# nrf5340_network register map
Vendor: Nordic Semiconductor; Series: nrf53; File version: 1
CPU: CM33 r0p4, little endian, MPU, no FPU, 3 interrupt priority bits, 30 interrupts
Registers are 32-bit, read-write, reset 0x0 unless marked. A register's access mark holds for its fields unless they carry their own. Offsets are from the block's base; [hi:lo] are bit positions; lines under a group give offsets from that group; {n}, {i} and the like mark numbered series; 'fields as' and 'values as' point back to an identical list.

## AAR_NS — Accelerated Address Resolver
Base 0x4100E000
0x00 TASKS_START wo — Start resolving addresses based on IRKs specified in the IRK data structure
  [0] TASKS_START
    1=Trigger task
0x08 TASKS_STOP wo — Stop resolving addresses
  [0] TASKS_STOP
    1=Trigger task
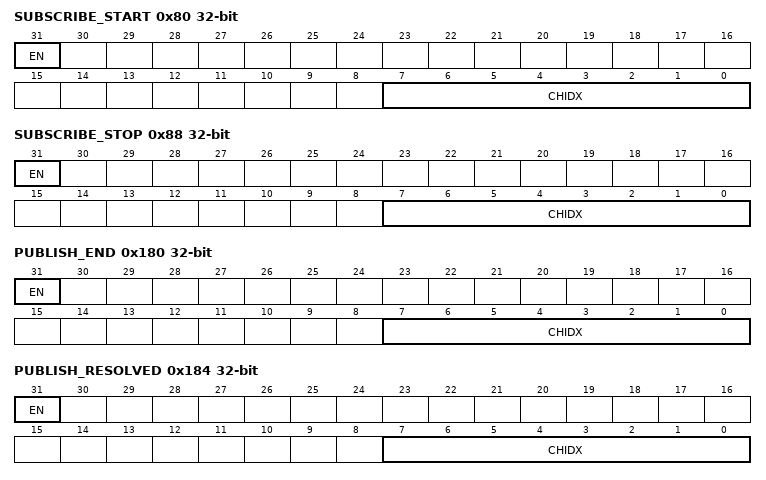
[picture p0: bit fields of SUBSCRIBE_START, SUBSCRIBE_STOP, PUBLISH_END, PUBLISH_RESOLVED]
0x80 SUBSCRIBE_START — Subscribe configuration for task START
  [31] EN
    0=Disabled (Disable subscription); 1=Enabled (Enable subscription)
  [7:0] CHIDX — DPPI channel that task START will subscribe to
0x88 SUBSCRIBE_STOP — Subscribe configuration for task STOP
  [31] EN
    values as SUBSCRIBE_START.EN
  [7:0] CHIDX — DPPI channel that task STOP will subscribe to
0x100 EVENTS_END — Address resolution procedure complete
  [0] EVENTS_END
    0=NotGenerated (Event not generated); 1=Generated (Event generated)
0x104 EVENTS_RESOLVED — Address resolved
  [0] EVENTS_RESOLVED
    values as EVENTS_END.EVENTS_END
0x108 EVENTS_NOTRESOLVED — Address not resolved
  [0] EVENTS_NOTRESOLVED
    values as EVENTS_END.EVENTS_END
0x180 PUBLISH_END — Publish configuration for event END
  [31] EN
    0=Disabled (Disable publishing); 1=Enabled (Enable publishing)
  [7:0] CHIDX — DPPI channel that event END will publish to.
0x184 PUBLISH_RESOLVED — Publish configuration for event RESOLVED
  [31] EN
    values as PUBLISH_END.EN
  [7:0] CHIDX — DPPI channel that event RESOLVED will publish to.
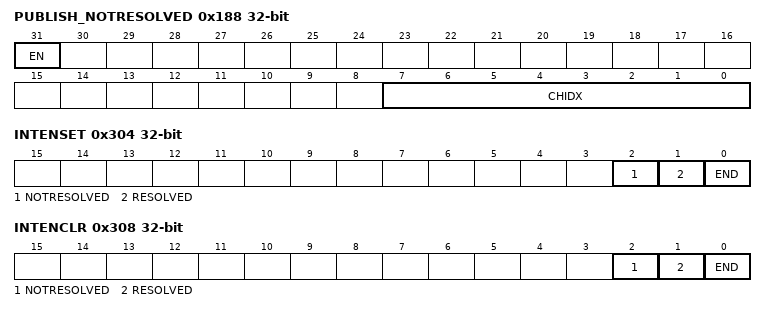
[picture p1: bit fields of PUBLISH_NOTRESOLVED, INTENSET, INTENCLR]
0x188 PUBLISH_NOTRESOLVED — Publish configuration for event NOTRESOLVED
  [31] EN
    values as PUBLISH_END.EN
  [7:0] CHIDX — DPPI channel that event NOTRESOLVED will publish to.
0x304 INTENSET — Enable interrupt
  [all] fields
    on read: 0=Disabled (Read: Disabled); 1=Enabled (Read: Enabled) | on write: 1=Set (Enable)
  [2] NOTRESOLVED — Write '1' to enable interrupt for event NOTRESOLVED
  [1] RESOLVED — Write '1' to enable interrupt for event RESOLVED
  [0] END — Write '1' to enable interrupt for event END
0x308 INTENCLR — Disable interrupt
  [all] fields
    on read: 0=Disabled (Read: Disabled); 1=Enabled (Read: Enabled) | on write: 1=Clear (Disable)
  [2] NOTRESOLVED — Write '1' to disable interrupt for event NOTRESOLVED
  [1] RESOLVED — Write '1' to disable interrupt for event RESOLVED
  [0] END — Write '1' to disable interrupt for event END
0x400 STATUS ro — Resolution status
  [3:0] STATUS — The IRK that was used last time an address was resolved
0x500 ENABLE — Enable AAR
  [1:0] ENABLE — Enable or disable AAR
    0=Disabled; 3=Enabled
0x504 NIRK reset 0x1 — Number of IRKs
  [4:0] NIRK — Number of Identity Root Keys available in the IRK data structure
0x508 IRKPTR — Pointer to IRK data structure
  [31:0] IRKPTR — Pointer to the IRK data structure
0x510 ADDRPTR — Pointer to the resolvable address
  [31:0] ADDRPTR — Pointer to the resolvable address (6-bytes)
0x514 SCRATCHPTR — Pointer to data area used for temporary storage
  [31:0] SCRATCHPTR — Pointer to a scratch data area used for temporary storage during resolution. A space of minimum 3 bytes must be reserved.

## DPPIC_NS — Distributed programmable peripheral interconnect controller
Base 0x4100F000
{0x0+8i} TASKS_CHG[{i}] (i=0..5) group — Channel group tasks
  0x00 EN wo — Description cluster: Enable channel group n
    [0] EN — Enable channel group n
      1=Trigger task
  0x04 DIS wo — Description cluster: Disable channel group n
    [0] DIS — Disable channel group n
      1=Trigger task
{0x80+8i} SUBSCRIBE_CHG[{i}] (i=0..5) group — Subscribe configuration for tasks
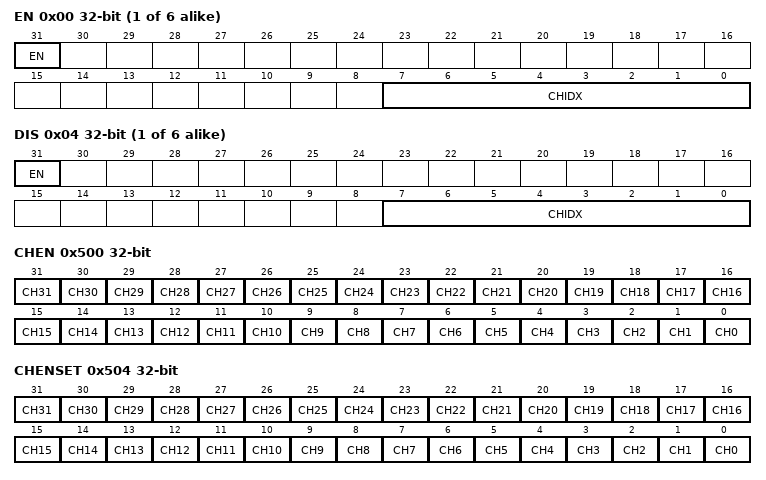
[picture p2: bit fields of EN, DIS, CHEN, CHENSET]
  0x00 EN — Description cluster: Subscribe configuration for task CHG[n].EN
    [31] EN
      0=Disabled (Disable subscription); 1=Enabled (Enable subscription)
    [7:0] CHIDX — DPPI channel that task CHG[n].EN will subscribe to
  0x04 DIS — Description cluster: Subscribe configuration for task CHG[n].DIS
    [31] EN
      values as SUBSCRIBE_CHG[0].EN.EN
    [7:0] CHIDX — DPPI channel that task CHG[n].DIS will subscribe to
0x500 CHEN — Channel enable register
  [all] fields
    0=Disabled (Disable channel); 1=Enabled (Enable channel)
  [n] CH{n} (n=0..31) — Enable or disable channel {n}
0x504 CHENSET write-1-sets — Channel enable set register
  [all] fields
    on read: 0=Disabled (Read: Channel disabled); 1=Enabled (Read: Channel enabled) | on write: 1=Set (Write: Enable channel)
  [n] CH{n} (n=0..31) — Channel {n} enable set register. Writing 0 has no effect.
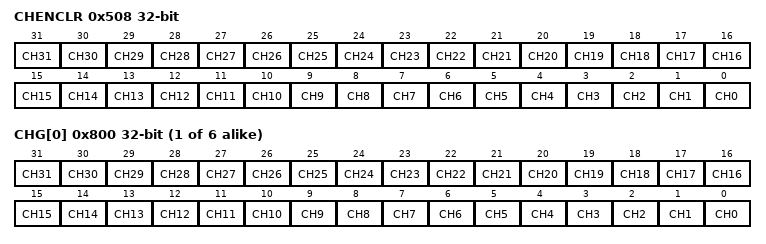
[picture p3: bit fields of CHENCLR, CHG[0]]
0x508 CHENCLR write-1-clears — Channel enable clear register
  [all] fields
    on read: 0=Disabled (Read: Channel disabled); 1=Enabled (Read: Channel enabled) | on write: 1=Clear (Write: Disable channel)
  [n] CH{n} (n=0..31) — Channel {n} enable clear register. Writing 0 has no effect.
{0x800+4i} CHG[{i}] (i=0..5) — Description collection: Channel group n Note: Writes to this register are ignored if either SUBSCRIBE_CHG[n].EN or SUBSCRIBE_CHG[n].DIS is enabled
  [all] fields
    0=Excluded; 1=Included
  [n] CH{n} (n=0..31) — Include or exclude channel {n}

## Notices in the file
Copyright (c) 2010 - 2024, Nordic Semiconductor ASA All rights reserved.
SPDX-License-Identifier: BSD-3-Clause
Redistribution and use in source and binary forms, with or without
modification, are permitted provided that the following conditions are met:
1. Redistributions of source code must retain the above copyright notice, this
list of conditions and the following disclaimer.
2. Redistributions in binary form must reproduce the above copyright
notice, this list of conditions and the following disclaimer in the
documentation and/or other materials provided with the distribution.
3. Neither the name of Nordic Semiconductor ASA nor the names of its
contributors may be used to endorse or promote products derived from this
software without specific prior written permission.
THIS SOFTWARE IS PROVIDED BY THE COPYRIGHT HOLDERS AND CONTRIBUTORS "AS IS"
AND ANY EXPRESS OR IMPLIED WARRANTIES, INCLUDING, BUT NOT LIMITED TO, THE
IMPLIED WARRANTIES OF MERCHANTABILITY, AND FITNESS FOR A PARTICULAR PURPOSE
ARE DISCLAIMED. IN NO EVENT SHALL NORDIC SEMICONDUCTOR ASA OR CONTRIBUTORS BE
LIABLE FOR ANY DIRECT, INDIRECT, INCIDENTAL, SPECIAL, EXEMPLARY, OR
CONSEQUENTIAL DAMAGES (INCLUDING, BUT NOT LIMITED TO, PROCUREMENT OF
SUBSTITUTE GOODS OR SERVICES; LOSS OF USE, DATA, OR PROFITS; OR BUSINESS
INTERRUPTION) HOWEVER CAUSED AND ON ANY THEORY OF LIABILITY, WHETHER IN
CONTRACT, STRICT LIABILITY, OR TORT (INCLUDING NEGLIGENCE OR OTHERWISE)
ARISING IN ANY WAY OUT OF THE USE OF THIS SOFTWARE, EVEN IF ADVISED OF THE
POSSIBILITY OF SUCH DAMAGE.
